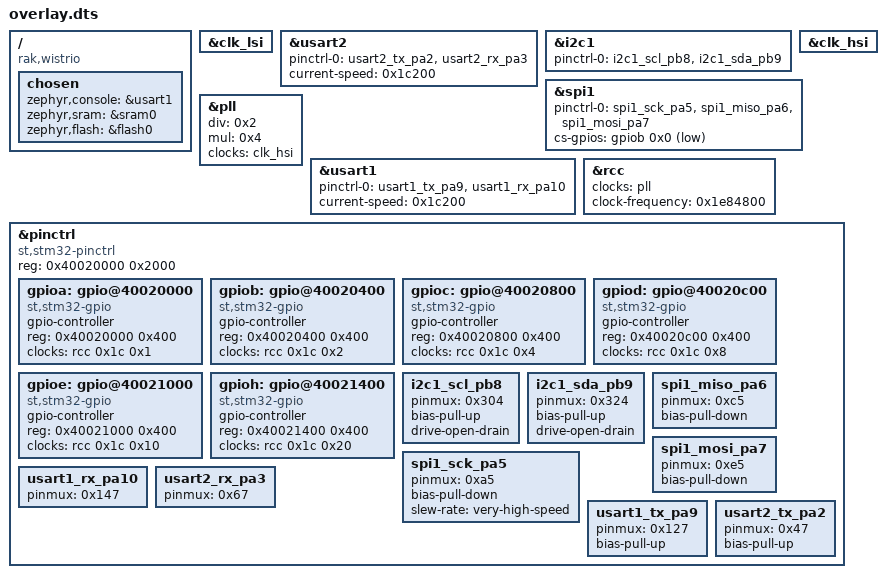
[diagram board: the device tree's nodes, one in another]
/ {
	compatible = "rak,wistrio";
	chosen {
		zephyr,console = &usart1;
		zephyr,sram = &sram0;
		zephyr,flash = &flash0;
	};
};
&clk_lsi{
	status = "okay";
};
&usart2{
	status = "okay";
	pinctrl-0 = < &usart2_tx_pa2 &usart2_rx_pa3 >;
	pinctrl-names = "default";
	current-speed = < 0x1c200 >;
};
&i2c1{
	status = "okay";
	pinctrl-0 = < &i2c1_scl_pb8 &i2c1_sda_pb9 >;
	pinctrl-names = "default";
};
&clk_hsi{
	status = "okay";
};
&spi1{
	status = "okay";
	pinctrl-0 = < &spi1_sck_pa5 &spi1_miso_pa6 &spi1_mosi_pa7 >;
	pinctrl-names = "default";
	cs-gpios = < &gpiob 0x0 0x1 >;
};
&pll{
	status = "okay";
	div = < 0x2 >;
	mul = < 0x4 >;
	clocks = < &clk_hsi >;
};
&usart1{
	status = "okay";
	pinctrl-0 = < &usart1_tx_pa9 &usart1_rx_pa10 >;
	pinctrl-names = "default";
	current-speed = < 0x1c200 >;
};
&rcc{
	clocks = < &pll >;
	clock-frequency = < 0x1e84800 >;
};
&pinctrl{
	compatible = "st,stm32-pinctrl";
	#address-cells = < 0x1 >;
	#size-cells = < 0x1 >;
	reg = < 0x40020000 0x2000 >;
	gpioa: gpio@40020000 {
		compatible = "st,stm32-gpio";
		gpio-controller;
		#gpio-cells = < 0x2 >;
		reg = < 0x40020000 0x400 >;
		clocks = < &rcc 0x1c 0x1 >;
	};
	gpiob: gpio@40020400 {
		compatible = "st,stm32-gpio";
		gpio-controller;
		#gpio-cells = < 0x2 >;
		reg = < 0x40020400 0x400 >;
		clocks = < &rcc 0x1c 0x2 >;
	};
	gpioc: gpio@40020800 {
		compatible = "st,stm32-gpio";
		gpio-controller;
		#gpio-cells = < 0x2 >;
		reg = < 0x40020800 0x400 >;
		clocks = < &rcc 0x1c 0x4 >;
	};
	gpiod: gpio@40020c00 {
		compatible = "st,stm32-gpio";
		gpio-controller;
		#gpio-cells = < 0x2 >;
		reg = < 0x40020c00 0x400 >;
		clocks = < &rcc 0x1c 0x8 >;
	};
	gpioe: gpio@40021000 {
		compatible = "st,stm32-gpio";
		gpio-controller;
		#gpio-cells = < 0x2 >;
		reg = < 0x40021000 0x400 >;
		clocks = < &rcc 0x1c 0x10 >;
	};
	gpioh: gpio@40021400 {
		compatible = "st,stm32-gpio";
		gpio-controller;
		#gpio-cells = < 0x2 >;
		reg = < 0x40021400 0x400 >;
		clocks = < &rcc 0x1c 0x20 >;
	};
	i2c1_scl_pb8: i2c1_scl_pb8 {
		pinmux = < 0x304 >;
		bias-pull-up;
		drive-open-drain;
	};
	i2c1_sda_pb9: i2c1_sda_pb9 {
		pinmux = < 0x324 >;
		bias-pull-up;
		drive-open-drain;
	};
	spi1_miso_pa6: spi1_miso_pa6 {
		pinmux = < 0xc5 >;
		bias-pull-down;
	};
	spi1_mosi_pa7: spi1_mosi_pa7 {
		pinmux = < 0xe5 >;
		bias-pull-down;
	};
	spi1_sck_pa5: spi1_sck_pa5 {
		pinmux = < 0xa5 >;
		bias-pull-down;
		slew-rate = "very-high-speed";
	};
	usart1_rx_pa10: usart1_rx_pa10 {
		pinmux = < 0x147 >;
	};
	usart2_rx_pa3: usart2_rx_pa3 {
		pinmux = < 0x67 >;
	};
	usart1_tx_pa9: usart1_tx_pa9 {
		pinmux = < 0x127 >;
		bias-pull-up;
	};
	usart2_tx_pa2: usart2_tx_pa2 {
		pinmux = < 0x47 >;
		bias-pull-up;
	};
};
